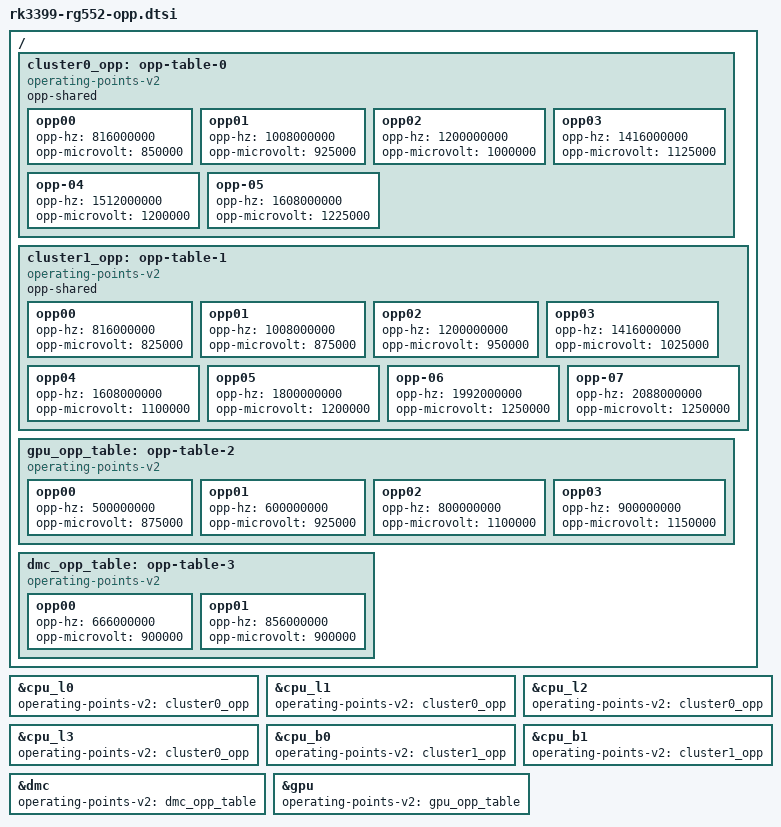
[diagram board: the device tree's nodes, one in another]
// SPDX-License-Identifier: (GPL-2.0+ OR MIT)
/*
 * Copyright (c) 2016-2017 Fuzhou Rockchip Electronics Co., Ltd
 * Copyright (C) 2023 BrooksyTech (https://github.com/brooksytech)
 */

/ {
	cluster0_opp: opp-table-0 {
		compatible = "operating-points-v2";
		opp-shared;

		opp00 {
			opp-hz = /bits/ 64 <816000000>;
			opp-microvolt = <850000>;
		};
		opp01 {
			opp-hz = /bits/ 64 <1008000000>;
			opp-microvolt = <925000>;
		};
		opp02 {
			opp-hz = /bits/ 64 <1200000000>;
			opp-microvolt = <1000000>;
		};
		opp03 {
			opp-hz = /bits/ 64 <1416000000>;
			opp-microvolt = <1125000>;
		};
		opp-04 {
			opp-hz = /bits/ 64 <1512000000>;
			opp-microvolt = <1200000>;
		};
		opp-05 {
			opp-hz = /bits/ 64 <1608000000>;
			opp-microvolt = <1225000>;
		};
	};

	cluster1_opp: opp-table-1 {
		compatible = "operating-points-v2";
		opp-shared;

		opp00 {
			opp-hz = /bits/ 64 <816000000>;
			opp-microvolt = <825000>;
		};
		opp01 {
			opp-hz = /bits/ 64 <1008000000>;
			opp-microvolt = <875000>;
		};
		opp02 {
			opp-hz = /bits/ 64 <1200000000>;
			opp-microvolt = <950000>;
		};
		opp03 {
			opp-hz = /bits/ 64 <1416000000>;
			opp-microvolt = <1025000>;
		};
		opp04 {
			opp-hz = /bits/ 64 <1608000000>;
			opp-microvolt = <1100000>;
		};
		opp05 {
			opp-hz = /bits/ 64 <1800000000>;
			opp-microvolt = <1200000>;
		};
		opp-06 {
			opp-hz = /bits/ 64 <1992000000>;
			opp-microvolt = <1250000>;
		};
		opp-07 {
			opp-hz = /bits/ 64 <2088000000>;
			opp-microvolt = <1250000>;
		};
	};

	gpu_opp_table: opp-table-2 {
		compatible = "operating-points-v2";

		opp00 {
			opp-hz = /bits/ 64 <500000000>;
			opp-microvolt = <875000>;
		};
		opp01 {
			opp-hz = /bits/ 64 <600000000>;
			opp-microvolt = <925000>;
		};
		opp02 {
			opp-hz = /bits/ 64 <800000000>;
			opp-microvolt = <1100000>;
		};
		opp03 {
			opp-hz = /bits/ 64 <900000000>;
			opp-microvolt = <1150000>;
		};
	};

        dmc_opp_table: opp-table-3 {
                compatible = "operating-points-v2";

		opp00 {
			opp-hz = /bits/ 64 <666000000>;
			opp-microvolt = <900000>;
		};
		opp01 {
			opp-hz = /bits/ 64 <856000000>;
			opp-microvolt = <900000>;
		};
        };
};

&cpu_l0 {
	operating-points-v2 = <&cluster0_opp>;
};

&cpu_l1 {
	operating-points-v2 = <&cluster0_opp>;
};

&cpu_l2 {
	operating-points-v2 = <&cluster0_opp>;
};

&cpu_l3 {
	operating-points-v2 = <&cluster0_opp>;
};

&cpu_b0 {
	operating-points-v2 = <&cluster1_opp>;
};

&cpu_b1 {
	operating-points-v2 = <&cluster1_opp>;
};

&dmc {
        operating-points-v2 = <&dmc_opp_table>;
};

&gpu {
	operating-points-v2 = <&gpu_opp_table>;
};
